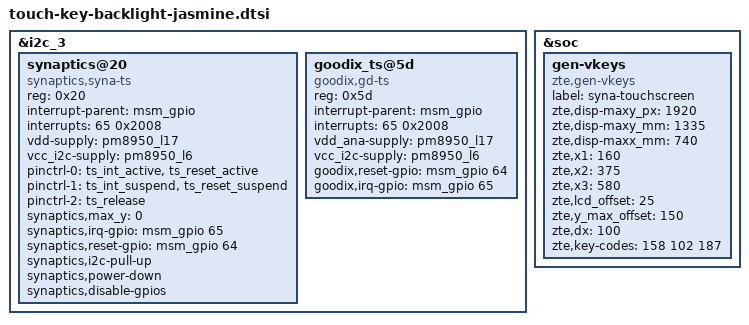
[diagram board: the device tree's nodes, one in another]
//for touchscreen and key and keypad-backlight


&i2c_3 { /* BLSP1 QUP3 */
			synaptics@20 {
				compatible = "synaptics,syna-ts";
				reg = <0x20>;
				interrupt-parent = <&msm_gpio>;
				interrupts = <65 0x2008>;
				vdd-supply = <&pm8950_l17>;
				vcc_i2c-supply = <&pm8950_l6>;
				/* pins used by touchscreen */
				pinctrl-names = "pmx_ts_active","pmx_ts_suspend","pmx_ts_release";
				pinctrl-0 = <&ts_int_active &ts_reset_active>;
				pinctrl-1 = <&ts_int_suspend &ts_reset_suspend>;
				pinctrl-2 = <&ts_release>;
				synaptics,max_y = <0>;
				synaptics,irq-gpio = <&msm_gpio 65 0x2008>;
				synaptics,reset-gpio = <&msm_gpio 64 0x0>;
				synaptics,i2c-pull-up;
				synaptics,power-down;
				synaptics,disable-gpios;

		};
		goodix_ts@5d {
				compatible = "goodix,gd-ts";
				reg = <0x5d>;
				interrupt-parent = <&msm_gpio>;
				interrupts = <65 0x2008>;
				vdd_ana-supply = <&pm8950_l17>;
				vcc_i2c-supply = <&pm8950_l6>;
				goodix,reset-gpio = <&msm_gpio 64 0x00>;
				goodix,irq-gpio = <&msm_gpio 65 0x00>;
		};

};

&soc {
		
	gen-vkeys {
		compatible = "zte,gen-vkeys";
		label = "syna-touchscreen";
		zte,disp-maxy_px = <1920>;
		zte,disp-maxy_mm = <1335>;//0.1mm
		zte,disp-maxx_mm = <740>;//0.1mm
		zte,x1=<160>;
		zte,x2=<375>;
		zte,x3=<580>;
		zte,lcd_offset=<25>;//距离LCD至少2mm 这里再放宽0.5mm
		zte,y_max_offset=<150>;//默认值LCD下边沿到按键下边沿距离估计取大值做余量
		zte,dx=<100>;//标准中X范围为5mm+-1mm取中值*2
		zte,key-codes = <158 102 187>;
	};	
};
/*
	gpio_keys {
		compatible = "gpio-keys";
		input-name = "gpio-keys";
		pinctrl-names = "tlmm_gpio_key_active","tlmm_gpio_key_suspend";
		pinctrl-0 = <&gpio_key_active>;
		pinctrl-1 = <&gpio_key_suspend>;

		//camera_focus {
		//	label = "camera_focus";
		//	gpios = <&msm_gpio 108 0x1>;
		//	linux,input-type = <1>;
		//	linux,code = <0x210>;
		//	gpio-key,wakeup;
		//	debounce-interval = <15>;
		//};

		camera_snapshot {
			label = "camera_snapshot";
			gpios = <&msm_gpio 108 0x1>;
			linux,input-type = <1>;
			linux,code = <0x2fe>;
			gpio-key,wakeup;
			debounce-interval = <15>;
		};

		vol_up {
			label = "volume_up";
			gpios = <&msm_gpio 107 0x1>;
			linux,input-type = <1>;
			linux,code = <115>;
			gpio-key,wakeup;
			debounce-interval = <15>;
		};
		vol_down {
			label = "volume_down";
			gpios = <&msm_gpio 109 0x1>;
			linux,input-type = <1>;
			linux,code = <114>;
			gpio-key,wakeup;
			debounce-interval = <15>;
		};		
	};

	gpio-leds {
		compatible = "gpio-leds";
		status = "okay";
		pinctrl-names = "default";
		pinctrl-0 = <&button_backlight_off>;

		keypad-backlight {
			gpios = <&msm_gpio 116 0>;
			label = "button-backlight";
			linux,default-trigger = "none";
		};
	};
*/



